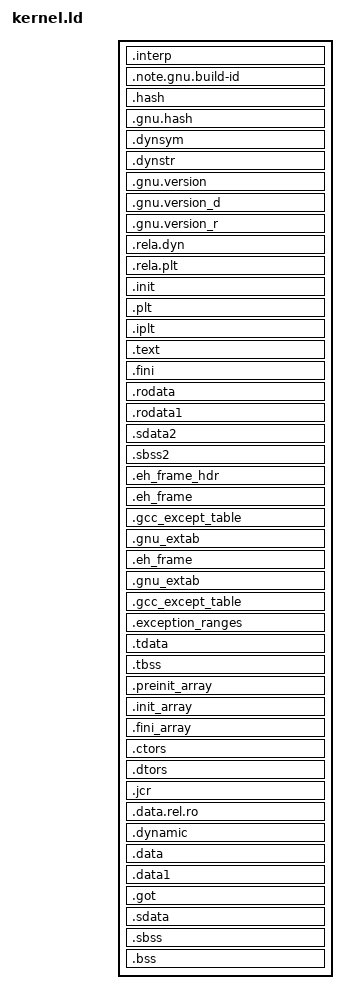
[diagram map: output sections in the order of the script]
OUTPUT_FORMAT("elf32-littlearm", "elf32-littlearm", "elf32-littlearm")
OUTPUT_ARCH(arm)

ENTRY(_start)
SECTIONS
{
  . = 0x80000000 + SIZEOF_HEADERS;

  .interp         : { *(.interp) }
  .note.gnu.build-id : { *(.note.gnu.build-id) }
  .hash           : { *(.hash) }
  .gnu.hash       : { *(.gnu.hash) }
  .dynsym         : { *(.dynsym) }
  .dynstr         : { *(.dynstr) }
  .gnu.version    : { *(.gnu.version) }
  .gnu.version_d  : { *(.gnu.version_d) }
  .gnu.version_r  : { *(.gnu.version_r) }
  .rela.dyn       :
    {
      *(.rela.init)
      *(.rela.text .rela.text.* .rela.gnu.linkonce.t.*)
      *(.rela.fini)
      *(.rela.rodata .rela.rodata.* .rela.gnu.linkonce.r.*)
      *(.rela.data .rela.data.* .rela.gnu.linkonce.d.*)
      *(.rela.tdata .rela.tdata.* .rela.gnu.linkonce.td.*)
      *(.rela.tbss .rela.tbss.* .rela.gnu.linkonce.tb.*)
      *(.rela.ctors)
      *(.rela.dtors)
      *(.rela.got)
      *(.rela.sdata .rela.sdata.* .rela.gnu.linkonce.s.*)
      *(.rela.sbss .rela.sbss.* .rela.gnu.linkonce.sb.*)
      *(.rela.sdata2 .rela.sdata2.* .rela.gnu.linkonce.s2.*)
      *(.rela.sbss2 .rela.sbss2.* .rela.gnu.linkonce.sb2.*)
      *(.rela.bss .rela.bss.* .rela.gnu.linkonce.b.*)
      PROVIDE_HIDDEN (__rela_iplt_start = .);
      *(.rela.iplt)
      PROVIDE_HIDDEN (__rela_iplt_end = .);
    }
  .rela.plt       :
    {
      *(.rela.plt)
    }
  .init           :
  {
    KEEP (*(SORT_NONE(.init)))
  }
  .plt            : { *(.plt) }
  .iplt           : { *(.iplt) }
  .text           :
  {
    *(.text.unlikely .text.*_unlikely .text.unlikely.*)
    *(.text.exit .text.exit.*)
    *(.text.startup .text.startup.*)
    *(.text.hot .text.hot.*)
    *(.text .stub .text.* .gnu.linkonce.t.*)
    /* .gnu.warning sections are handled specially by elf32.em.  */
    *(.gnu.warning)
  }
  .fini           :
  {
    KEEP (*(SORT_NONE(.fini)))
  }
  PROVIDE (__etext = .);
  PROVIDE (_etext = .);
  PROVIDE (etext = .);
  .rodata         : { *(.rodata .rodata.* .gnu.linkonce.r.*) }
  .rodata1        : { *(.rodata1) }
  .sdata2         :
  {
    *(.sdata2 .sdata2.* .gnu.linkonce.s2.*)
  }
  .sbss2          : { *(.sbss2 .sbss2.* .gnu.linkonce.sb2.*) }
  .eh_frame_hdr : { *(.eh_frame_hdr) *(.eh_frame_entry .eh_frame_entry.*) }
  .eh_frame       : ONLY_IF_RO { KEEP (*(.eh_frame)) *(.eh_frame.*) }
  .gcc_except_table   : ONLY_IF_RO { *(.gcc_except_table
  .gcc_except_table.*) }
  .gnu_extab   : ONLY_IF_RO { *(.gnu_extab*) }
  /* Adjust the address for the data segment.  We want to adjust up to
   * the same address within the page on the next page up. */
  . = DATA_SEGMENT_ALIGN (CONSTANT (MAXPAGESIZE), CONSTANT (COMMONPAGESIZE));
  /* Exception handling  */
  .eh_frame       : ONLY_IF_RW { KEEP (*(.eh_frame)) *(.eh_frame.*) }
  .gnu_extab      : ONLY_IF_RW { *(.gnu_extab) }
  .gcc_except_table   : ONLY_IF_RW { *(.gcc_except_table .gcc_except_table.*) }
  .exception_ranges   : ONLY_IF_RW { *(.exception_ranges .exception_ranges*) }
  /* Thread Local Storage sections  */
  .tdata	  : { *(.tdata .tdata.* .gnu.linkonce.td.*) }
  .tbss		  : { *(.tbss .tbss.* .gnu.linkonce.tb.*) *(.tcommon) }
  .preinit_array     :
  {
    PROVIDE_HIDDEN (__preinit_array_start = .);
    KEEP (*(.preinit_array))
    PROVIDE_HIDDEN (__preinit_array_end = .);
  }
  .init_array     :
  {
    PROVIDE_HIDDEN (__init_array_start = .);
    KEEP (*(SORT_BY_INIT_PRIORITY(.init_array.*) SORT_BY_INIT_PRIORITY(.ctors.*)))
    KEEP (*(.init_array EXCLUDE_FILE (*crtbegin.o *crtbegin?.o *crtend.o *crtend?.o ) .ctors))
    PROVIDE_HIDDEN (__init_array_end = .);
  }
  .fini_array     :
  {
    PROVIDE_HIDDEN (__fini_array_start = .);
    KEEP (*(SORT_BY_INIT_PRIORITY(.fini_array.*) SORT_BY_INIT_PRIORITY(.dtors.*)))
    KEEP (*(.fini_array EXCLUDE_FILE (*crtbegin.o *crtbegin?.o *crtend.o *crtend?.o ) .dtors))
    PROVIDE_HIDDEN (__fini_array_end = .);
  }
  .ctors          :
  {
    /* gcc uses crtbegin.o to find the start of
     * the constructors, so we make sure it is
     * first.  Because this is a wildcard, it
     * doesn't matter if the user does not
     * actually link against crtbegin.o; the
     * linker won't look for a file to match a
     * wildcard.  The wildcard also means that it
     * doesn't matter which directory crtbegin.o
     * is in.  */
    KEEP (*crtbegin.o(.ctors))
    KEEP (*crtbegin?.o(.ctors))
    /* We don't want to include the .ctor section from
     * the crtend.o file until after the sorted ctors.
     * The .ctor section from the crtend file contains the
     * end of ctors marker and it must be last */
    KEEP (*(EXCLUDE_FILE (*crtend.o *crtend?.o ) .ctors))
    KEEP (*(SORT(.ctors.*)))
    KEEP (*(.ctors))
  }
  .dtors          :
  {
    KEEP (*crtbegin.o(.dtors))
    KEEP (*crtbegin?.o(.dtors))
    KEEP (*(EXCLUDE_FILE (*crtend.o *crtend?.o ) .dtors))
    KEEP (*(SORT(.dtors.*)))
    KEEP (*(.dtors))
  }
  .jcr            : { KEEP (*(.jcr)) }
  .data.rel.ro : { *(.data.rel.ro.local* .gnu.linkonce.d.rel.ro.local.*) *(.data.rel.ro .data.rel.ro.* .gnu.linkonce.d.rel.ro.*) }
  .dynamic        : { *(.dynamic) }
  . = DATA_SEGMENT_RELRO_END (0, .);
  .data           :
  {
    *(.data .data.* .gnu.linkonce.d.*)
    SORT(CONSTRUCTORS)
  }
  .data1          : { *(.data1) }
  .got            : { *(.got.plt) *(.igot.plt) *(.got) *(.igot) }
  /* We want the small data sections together, so single-instruction offsets
   * can access them all, and initialized data all before uninitialized, so
   * we can shorten the on-disk segment size.  */
  .sdata          :
  {
    __global_pointer$ = . + 0x800;
    *(.srodata.cst16) *(.srodata.cst8) *(.srodata.cst4) *(.srodata.cst2) *(.srodata .srodata.*)
    *(.sdata .sdata.* .gnu.linkonce.s.*)
  }
  _edata = .; PROVIDE (edata = .);
  . = .;
  __bss_start = .;
  .sbss           :
  {
    *(.dynsbss)
    *(.sbss .sbss.* .gnu.linkonce.sb.*)
    *(.scommon)
  }
  .bss            :
  {
   *(.dynbss)
   *(.bss .bss.* .gnu.linkonce.b.*)
   *(COMMON)
   /* Align here to ensure that the .bss section occupies space up to
    * _end.  Align after .bss to ensure correct alignment even if the
    * .bss section disappears because there are no input sections.
    * FIXME: Why do we need it? When there is no .bss section, we don't
    * pad the .data section.  */
   . = ALIGN(. != 0 ? 64 / 8 : 1);
  }
  . = ALIGN(64 / 8);
  . = SEGMENT_START("ldata-segment", .);
  . = ALIGN(64 / 8);
  _end = .; PROVIDE (end = .);
  . = DATA_SEGMENT_END (.);
  /DISCARD/ : { *(.note.GNU-stack) *(.gnu_debuglink) *(.gnu.lto_*) }
}
